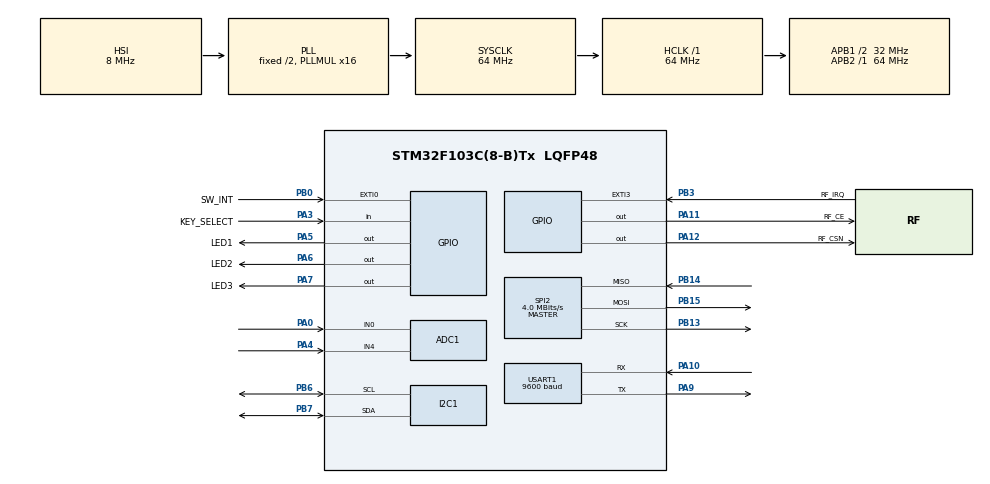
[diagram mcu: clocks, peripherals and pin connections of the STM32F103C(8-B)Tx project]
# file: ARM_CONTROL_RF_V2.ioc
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ADC1.Channel-0\#ChannelRegularConversion=ADC_CHANNEL_0
ADC1.Channel-1\#ChannelRegularConversion=ADC_CHANNEL_4
ADC1.ContinuousConvMode=ENABLE
ADC1.NbrOfConversion=2
ADC1.NbrOfConversionFlag=1
ADC1.Rank-0\#ChannelRegularConversion=1
ADC1.Rank-1\#ChannelRegularConversion=2
ADC1.SamplingTime-0\#ChannelRegularConversion=ADC_SAMPLETIME_13CYCLES_5
ADC1.SamplingTime-1\#ChannelRegularConversion=ADC_SAMPLETIME_13CYCLES_5
ADC1.master=1
I2C1.I2C_Mode=I2C_Fast
Mcu.Family=STM32F1
Mcu.Name=STM32F103C(8-B)Tx
Mcu.Package=LQFP48
NVIC.EXTI0_IRQn=true\:5\:0\:true\:false\:true\:true\:true\:true
NVIC.EXTI3_IRQn=true\:2\:0\:true\:false\:true\:true\:true\:true
NVIC.PriorityGroup=NVIC_PRIORITYGROUP_4
NVIC.TIM4_IRQn=true\:3\:0\:true\:false\:true\:true\:true\:true
PA0-WKUP.Signal=ADCx_IN0
PA10.Mode=Asynchronous
PA10.Signal=USART1_RX
PA11.GPIO_Label=RF_CE
PA11.Signal=GPIO_Output
PA12.GPIO_Label=RF_CSN
PA12.Signal=GPIO_Output
PA13.Mode=Serial_Wire
PA13.Signal=SYS_JTMS-SWDIO
PA14.Mode=Serial_Wire
PA14.Signal=SYS_JTCK-SWCLK
PA3.GPIO_Label=KEY_SELECT
PA3.GPIO_PuPd=GPIO_PULLUP
PA3.Signal=GPIO_Input
PA4.Signal=ADCx_IN4
PA5.GPIO_Label=LED1
PA5.Signal=GPIO_Output
PA6.GPIO_Label=LED2
PA6.Signal=GPIO_Output
PA7.GPIO_Label=LED3
PA7.Signal=GPIO_Output
PA9.Mode=Asynchronous
PA9.Signal=USART1_TX
PB0.GPIO_Label=SW_INT
PB0.GPIO_ModeDefaultEXTI=GPIO_MODE_IT_FALLING
PB0.GPIO_PuPd=GPIO_PULLUP
PB0.Signal=GPXTI0
PB13.Mode=Full_Duplex_Master
PB13.Signal=SPI2_SCK
PB14.GPIO_PuPd=GPIO_PULLDOWN
PB14.Mode=Full_Duplex_Master
PB14.Signal=SPI2_MISO
PB15.Mode=Full_Duplex_Master
PB15.Signal=SPI2_MOSI
PB3.GPIO_Label=RF_IRQ
PB3.GPIO_ModeDefaultEXTI=GPIO_MODE_IT_FALLING
PB3.GPIO_PuPd=GPIO_PULLUP
PB3.Signal=GPXTI3
PB6.GPIO_Pu=GPIO_PULLUP
PB6.Mode=I2C
PB6.Signal=I2C1_SCL
PB7.GPIO_Pu=GPIO_PULLUP
PB7.Mode=I2C
PB7.Signal=I2C1_SDA
ProjectManager.HeapSize=0x200
ProjectManager.StackSize=0x400
ProjectManager.TargetToolchain=STM32CubeIDE
RCC.ADCPresc=RCC_ADCPCLK2_DIV6
RCC.AHBFreq_Value=64000000
RCC.APB1CLKDivider=RCC_HCLK_DIV2
RCC.APB1Freq_Value=32000000
RCC.APB1TimFreq_Value=64000000
RCC.APB2Freq_Value=64000000
RCC.APB2TimFreq_Value=64000000
RCC.HCLKFreq_Value=64000000
RCC.PLLMUL=RCC_PLL_MUL16
RCC.SYSCLKFreq_VALUE=64000000
RCC.SYSCLKSource=RCC_SYSCLKSOURCE_PLLCLK
RCC.USBFreq_Value=64000000
SH.ADCx_IN0.0=ADC1_IN0,IN0
SH.ADCx_IN4.0=ADC1_IN4,IN4
SPI2.BaudRatePrescaler=SPI_BAUDRATEPRESCALER_8
SPI2.CalculateBaudRate=4.0 MBits/s
SPI2.DataSize=SPI_DATASIZE_8BIT
SPI2.Direction=SPI_DIRECTION_2LINES
SPI2.Mode=SPI_MODE_MASTER
SPI2.VirtualType=VM_MASTER
TIM2.Prescaler=63
TIM4.Period=199
TIM4.Prescaler=63999
USART1.BaudRate=9600
USART1.VirtualMode=VM_ASYNC
VP_TIM2_VS_ClockSourceINT.Mode=Internal
VP_TIM4_VS_ClockSourceINT.Mode=Internal
board=custom

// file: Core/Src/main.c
/* USER CODE BEGIN Header */
/**
  ******************************************************************************
  * @file           : main.c
  * @brief          : Main program body
  ******************************************************************************
  * @attention
  *
  * <h2><center>&copy; Copyright (c) 2021 STMicroelectronics.
  * All rights reserved.</center></h2>
  *
  * This software component is licensed by ST under BSD 3-Clause license,
  * the "License"; You may not use this file except in compliance with the
  * License. You may obtain a copy of the License at:
  *                        opensource.org/licenses/BSD-3-Clause
  *
  ******************************************************************************
  */
/* USER CODE END Header */
#include "main.h"

/* USER CODE BEGIN Includes */
#include "app.h"
/* USER CODE END Includes */

ADC_HandleTypeDef hadc1;

I2C_HandleTypeDef hi2c1;

SPI_HandleTypeDef hspi2;

TIM_HandleTypeDef htim2;
TIM_HandleTypeDef htim4;

UART_HandleTypeDef huart1;

void SystemClock_Config(void);
static void MX_GPIO_Init(void);
static void MX_I2C1_Init(void);
static void MX_SPI2_Init(void);
static void MX_TIM2_Init(void);
static void MX_ADC1_Init(void);
static void MX_USART1_UART_Init(void);
static void MX_TIM4_Init(void);

int main(void)
{

  /* MCU Configuration--------------------------------------------------------*/

  /* Reset of all peripherals, Initializes the Flash interface and the Systick. */
  HAL_Init();

  /* Configure the system clock */
  SystemClock_Config();

  /* Initialize all configured peripherals */
  MX_GPIO_Init();
  MX_I2C1_Init();
  MX_SPI2_Init();
  MX_TIM2_Init();
  MX_ADC1_Init();
  MX_USART1_UART_Init();
  MX_TIM4_Init();
  /* USER CODE BEGIN 2 */
  app_init();
  /* USER CODE END 2 */

  /* Infinite loop */
  /* USER CODE BEGIN WHILE */
  while (1)
  {
	app_loop();
		//HAL_GPIO_WritePin(LED1_GPIO_Port, LED1_Pin,SET);
		//HAL_GPIO_WritePin(LED2_GPIO_Port, LED2_Pin,SET);
		//HAL_GPIO_WritePin(LED3_GPIO_Port, LED3_Pin,SET);
    /* USER CODE END WHILE */

  }
}

void SystemClock_Config(void)
{
  RCC_OscInitTypeDef RCC_OscInitStruct = {0};
  RCC_ClkInitTypeDef RCC_ClkInitStruct = {0};
  RCC_PeriphCLKInitTypeDef PeriphClkInit = {0};

  /** Initializes the RCC Oscillators according to the specified parameters
  * in the RCC_OscInitTypeDef structure.
  */
  RCC_OscInitStruct.OscillatorType = RCC_OSCILLATORTYPE_HSI;
  RCC_OscInitStruct.HSIState = RCC_HSI_ON;
  RCC_OscInitStruct.HSICalibrationValue = RCC_HSICALIBRATION_DEFAULT;
  RCC_OscInitStruct.PLL.PLLState = RCC_PLL_ON;
  RCC_OscInitStruct.PLL.PLLSource = RCC_PLLSOURCE_HSI_DIV2;
  RCC_OscInitStruct.PLL.PLLMUL = RCC_PLL_MUL16;
  if (HAL_RCC_OscConfig(&RCC_OscInitStruct) != HAL_OK)
  {
    Error_Handler();
  }
  /** Initializes the CPU, AHB and APB buses clocks
  */
  RCC_ClkInitStruct.ClockType = RCC_CLOCKTYPE_HCLK|RCC_CLOCKTYPE_SYSCLK
                              |RCC_CLOCKTYPE_PCLK1|RCC_CLOCKTYPE_PCLK2;
  RCC_ClkInitStruct.SYSCLKSource = RCC_SYSCLKSOURCE_PLLCLK;
  RCC_ClkInitStruct.AHBCLKDivider = RCC_SYSCLK_DIV1;
  RCC_ClkInitStruct.APB1CLKDivider = RCC_HCLK_DIV2;
  RCC_ClkInitStruct.APB2CLKDivider = RCC_HCLK_DIV1;

  if (HAL_RCC_ClockConfig(&RCC_ClkInitStruct, FLASH_LATENCY_2) != HAL_OK)
  {
    Error_Handler();
  }
  PeriphClkInit.PeriphClockSelection = RCC_PERIPHCLK_ADC;
  PeriphClkInit.AdcClockSelection = RCC_ADCPCLK2_DIV6;
  if (HAL_RCCEx_PeriphCLKConfig(&PeriphClkInit) != HAL_OK)
  {
    Error_Handler();
  }
}

static void MX_ADC1_Init(void)
{

  ADC_ChannelConfTypeDef sConfig = {0};

  /** Common config
  */
  hadc1.Instance = ADC1;
  hadc1.Init.ScanConvMode = ADC_SCAN_ENABLE;
  hadc1.Init.ContinuousConvMode = ENABLE;
  hadc1.Init.DiscontinuousConvMode = DISABLE;
  hadc1.Init.ExternalTrigConv = ADC_SOFTWARE_START;
  hadc1.Init.DataAlign = ADC_DATAALIGN_RIGHT;
  hadc1.Init.NbrOfConversion = 2;
  if (HAL_ADC_Init(&hadc1) != HAL_OK)
  {
    Error_Handler();
  }
  /** Configure Regular Channel
  */
  sConfig.Channel = ADC_CHANNEL_0;
  sConfig.Rank = ADC_REGULAR_RANK_1;
  sConfig.SamplingTime = ADC_SAMPLETIME_13CYCLES_5;
  if (HAL_ADC_ConfigChannel(&hadc1, &sConfig) != HAL_OK)
  {
    Error_Handler();
  }
  /** Configure Regular Channel
  */
  sConfig.Channel = ADC_CHANNEL_4;
  sConfig.Rank = ADC_REGULAR_RANK_2;
  if (HAL_ADC_ConfigChannel(&hadc1, &sConfig) != HAL_OK)
  {
    Error_Handler();
  }

}

static void MX_I2C1_Init(void)
{

  hi2c1.Instance = I2C1;
  hi2c1.Init.ClockSpeed = 400000;
  hi2c1.Init.DutyCycle = I2C_DUTYCYCLE_2;
  hi2c1.Init.OwnAddress1 = 0;
  hi2c1.Init.AddressingMode = I2C_ADDRESSINGMODE_7BIT;
  hi2c1.Init.DualAddressMode = I2C_DUALADDRESS_DISABLE;
  hi2c1.Init.OwnAddress2 = 0;
  hi2c1.Init.GeneralCallMode = I2C_GENERALCALL_DISABLE;
  hi2c1.Init.NoStretchMode = I2C_NOSTRETCH_DISABLE;
  if (HAL_I2C_Init(&hi2c1) != HAL_OK)
  {
    Error_Handler();
  }

}

static void MX_SPI2_Init(void)
{

  /* SPI2 parameter configuration*/
  hspi2.Instance = SPI2;
  hspi2.Init.Mode = SPI_MODE_MASTER;
  hspi2.Init.Direction = SPI_DIRECTION_2LINES;
  hspi2.Init.DataSize = SPI_DATASIZE_8BIT;
  hspi2.Init.CLKPolarity = SPI_POLARITY_LOW;
  hspi2.Init.CLKPhase = SPI_PHASE_1EDGE;
  hspi2.Init.NSS = SPI_NSS_SOFT;
  hspi2.Init.BaudRatePrescaler = SPI_BAUDRATEPRESCALER_8;
  hspi2.Init.FirstBit = SPI_FIRSTBIT_MSB;
  hspi2.Init.TIMode = SPI_TIMODE_DISABLE;
  hspi2.Init.CRCCalculation = SPI_CRCCALCULATION_DISABLE;
  hspi2.Init.CRCPolynomial = 10;
  if (HAL_SPI_Init(&hspi2) != HAL_OK)
  {
    Error_Handler();
  }

}

static void MX_TIM2_Init(void)
{

  TIM_ClockConfigTypeDef sClockSourceConfig = {0};
  TIM_MasterConfigTypeDef sMasterConfig = {0};

  htim2.Instance = TIM2;
  htim2.Init.Prescaler = 63;
  htim2.Init.CounterMode = TIM_COUNTERMODE_UP;
  htim2.Init.Period = 65535;
  htim2.Init.ClockDivision = TIM_CLOCKDIVISION_DIV1;
  htim2.Init.AutoReloadPreload = TIM_AUTORELOAD_PRELOAD_DISABLE;
  if (HAL_TIM_Base_Init(&htim2) != HAL_OK)
  {
    Error_Handler();
  }
  sClockSourceConfig.ClockSource = TIM_CLOCKSOURCE_INTERNAL;
  if (HAL_TIM_ConfigClockSource(&htim2, &sClockSourceConfig) != HAL_OK)
  {
    Error_Handler();
  }
  sMasterConfig.MasterOutputTrigger = TIM_TRGO_RESET;
  sMasterConfig.MasterSlaveMode = TIM_MASTERSLAVEMODE_DISABLE;
  if (HAL_TIMEx_MasterConfigSynchronization(&htim2, &sMasterConfig) != HAL_OK)
  {
    Error_Handler();
  }

}

static void MX_TIM4_Init(void)
{

  TIM_ClockConfigTypeDef sClockSourceConfig = {0};
  TIM_MasterConfigTypeDef sMasterConfig = {0};

  htim4.Instance = TIM4;
  htim4.Init.Prescaler = 63999;
  htim4.Init.CounterMode = TIM_COUNTERMODE_UP;
  htim4.Init.Period = 199;
  htim4.Init.ClockDivision = TIM_CLOCKDIVISION_DIV1;
  htim4.Init.AutoReloadPreload = TIM_AUTORELOAD_PRELOAD_DISABLE;
  if (HAL_TIM_Base_Init(&htim4) != HAL_OK)
  {
    Error_Handler();
  }
  sClockSourceConfig.ClockSource = TIM_CLOCKSOURCE_INTERNAL;
  if (HAL_TIM_ConfigClockSource(&htim4, &sClockSourceConfig) != HAL_OK)
  {
    Error_Handler();
  }
  sMasterConfig.MasterOutputTrigger = TIM_TRGO_RESET;
  sMasterConfig.MasterSlaveMode = TIM_MASTERSLAVEMODE_DISABLE;
  if (HAL_TIMEx_MasterConfigSynchronization(&htim4, &sMasterConfig) != HAL_OK)
  {
    Error_Handler();
  }

}

static void MX_USART1_UART_Init(void)
{

  huart1.Instance = USART1;
  huart1.Init.BaudRate = 9600;
  huart1.Init.WordLength = UART_WORDLENGTH_8B;
  huart1.Init.StopBits = UART_STOPBITS_1;
  huart1.Init.Parity = UART_PARITY_NONE;
  huart1.Init.Mode = UART_MODE_TX_RX;
  huart1.Init.HwFlowCtl = UART_HWCONTROL_NONE;
  huart1.Init.OverSampling = UART_OVERSAMPLING_16;
  if (HAL_UART_Init(&huart1) != HAL_OK)
  {
    Error_Handler();
  }

}

static void MX_GPIO_Init(void)
{
  GPIO_InitTypeDef GPIO_InitStruct = {0};

  /* GPIO Ports Clock Enable */
  __HAL_RCC_GPIOA_CLK_ENABLE();
  __HAL_RCC_GPIOB_CLK_ENABLE();

  /*Configure GPIO pin Output Level */
  HAL_GPIO_WritePin(GPIOA, LED1_Pin|LED2_Pin|LED3_Pin|RF_CE_Pin
                          |RF_CSN_Pin, GPIO_PIN_RESET);

  /*Configure GPIO pin : KEY_SELECT_Pin */
  GPIO_InitStruct.Pin = KEY_SELECT_Pin;
  GPIO_InitStruct.Mode = GPIO_MODE_INPUT;
  GPIO_InitStruct.Pull = GPIO_PULLUP;
  HAL_GPIO_Init(KEY_SELECT_GPIO_Port, &GPIO_InitStruct);

  /*Configure GPIO pins : LED1_Pin LED2_Pin LED3_Pin RF_CE_Pin
                           RF_CSN_Pin */
  GPIO_InitStruct.Pin = LED1_Pin|LED2_Pin|LED3_Pin|RF_CE_Pin
                          |RF_CSN_Pin;
  GPIO_InitStruct.Mode = GPIO_MODE_OUTPUT_PP;
  GPIO_InitStruct.Pull = GPIO_NOPULL;
  GPIO_InitStruct.Speed = GPIO_SPEED_FREQ_LOW;
  HAL_GPIO_Init(GPIOA, &GPIO_InitStruct);

  /*Configure GPIO pins : SW_INT_Pin RF_IRQ_Pin */
  GPIO_InitStruct.Pin = SW_INT_Pin|RF_IRQ_Pin;
  GPIO_InitStruct.Mode = GPIO_MODE_IT_FALLING;
  GPIO_InitStruct.Pull = GPIO_PULLUP;
  HAL_GPIO_Init(GPIOB, &GPIO_InitStruct);

  /* EXTI interrupt init*/
  HAL_NVIC_SetPriority(EXTI0_IRQn, 5, 0);
  HAL_NVIC_EnableIRQ(EXTI0_IRQn);

  HAL_NVIC_SetPriority(EXTI3_IRQn, 2, 0);
  HAL_NVIC_EnableIRQ(EXTI3_IRQn);

}

void Error_Handler(void)
{
}

/************************ (C) COPYRIGHT STMicroelectronics *****END OF FILE****/
